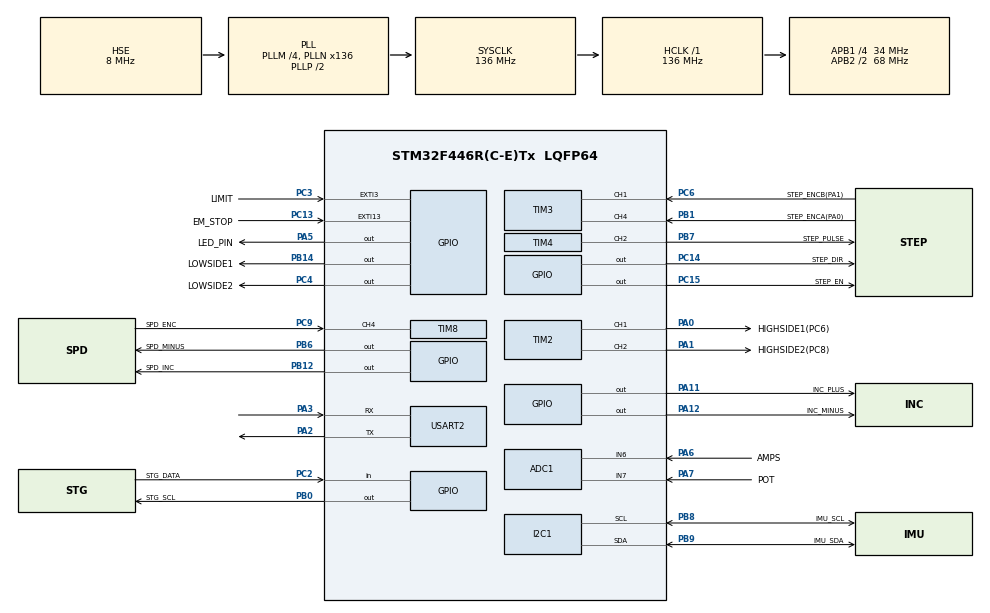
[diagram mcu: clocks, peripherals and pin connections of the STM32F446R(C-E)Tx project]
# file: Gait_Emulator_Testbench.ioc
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ADC1.Channel-2\#ChannelRegularConversion=ADC_CHANNEL_6
ADC1.NbrOfConversionFlag=1
ADC1.Rank-2\#ChannelRegularConversion=1
ADC1.SamplingTime-2\#ChannelRegularConversion=ADC_SAMPLETIME_3CYCLES
ADC1.master=1
Dma.ADC1.3.Direction=DMA_PERIPH_TO_MEMORY
Dma.ADC1.3.FIFOMode=DMA_FIFOMODE_DISABLE
Dma.ADC1.3.Instance=DMA2_Stream0
Dma.ADC1.3.MemDataAlignment=DMA_MDATAALIGN_HALFWORD
Dma.ADC1.3.MemInc=DMA_MINC_ENABLE
Dma.ADC1.3.Mode=DMA_CIRCULAR
Dma.ADC1.3.PeriphDataAlignment=DMA_PDATAALIGN_HALFWORD
Dma.ADC1.3.PeriphInc=DMA_PINC_DISABLE
Dma.ADC1.3.Priority=DMA_PRIORITY_LOW
Dma.I2C1_RX.4.Direction=DMA_PERIPH_TO_MEMORY
Dma.I2C1_RX.4.FIFOMode=DMA_FIFOMODE_DISABLE
Dma.I2C1_RX.4.Instance=DMA1_Stream0
Dma.I2C1_RX.4.MemDataAlignment=DMA_MDATAALIGN_BYTE
Dma.I2C1_RX.4.MemInc=DMA_MINC_ENABLE
Dma.I2C1_RX.4.Mode=DMA_CIRCULAR
Dma.I2C1_RX.4.PeriphDataAlignment=DMA_PDATAALIGN_BYTE
Dma.I2C1_RX.4.PeriphInc=DMA_PINC_DISABLE
Dma.I2C1_RX.4.Priority=DMA_PRIORITY_LOW
Dma.I2C1_TX.5.Direction=DMA_MEMORY_TO_PERIPH
Dma.I2C1_TX.5.FIFOMode=DMA_FIFOMODE_DISABLE
Dma.I2C1_TX.5.Instance=DMA1_Stream7
Dma.I2C1_TX.5.MemDataAlignment=DMA_MDATAALIGN_BYTE
Dma.I2C1_TX.5.MemInc=DMA_MINC_ENABLE
Dma.I2C1_TX.5.Mode=DMA_CIRCULAR
Dma.I2C1_TX.5.PeriphDataAlignment=DMA_PDATAALIGN_BYTE
Dma.I2C1_TX.5.PeriphInc=DMA_PINC_DISABLE
Dma.I2C1_TX.5.Priority=DMA_PRIORITY_LOW
Dma.Request0=TIM8_CH4/TRIG/COM
Dma.Request1=USART2_RX
Dma.Request2=USART2_TX
Dma.Request3=ADC1
Dma.Request4=I2C1_RX
Dma.Request5=I2C1_TX
Dma.Request6=TIM3_CH1/TRIG
Dma.Request7=TIM3_CH4/UP
Dma.TIM3_CH1/TRIG.6.Direction=DMA_PERIPH_TO_MEMORY
Dma.TIM3_CH1/TRIG.6.FIFOMode=DMA_FIFOMODE_DISABLE
Dma.TIM3_CH1/TRIG.6.Instance=DMA1_Stream4
Dma.TIM3_CH1/TRIG.6.MemDataAlignment=DMA_MDATAALIGN_HALFWORD
Dma.TIM3_CH1/TRIG.6.MemInc=DMA_MINC_ENABLE
Dma.TIM3_CH1/TRIG.6.Mode=DMA_CIRCULAR
Dma.TIM3_CH1/TRIG.6.PeriphDataAlignment=DMA_PDATAALIGN_HALFWORD
Dma.TIM3_CH1/TRIG.6.PeriphInc=DMA_PINC_DISABLE
Dma.TIM3_CH1/TRIG.6.Priority=DMA_PRIORITY_LOW
Dma.TIM3_CH4/UP.7.Direction=DMA_PERIPH_TO_MEMORY
Dma.TIM3_CH4/UP.7.FIFOMode=DMA_FIFOMODE_DISABLE
Dma.TIM3_CH4/UP.7.Instance=DMA1_Stream2
Dma.TIM3_CH4/UP.7.MemDataAlignment=DMA_MDATAALIGN_HALFWORD
Dma.TIM3_CH4/UP.7.MemInc=DMA_MINC_ENABLE
Dma.TIM3_CH4/UP.7.Mode=DMA_CIRCULAR
Dma.TIM3_CH4/UP.7.PeriphDataAlignment=DMA_PDATAALIGN_HALFWORD
Dma.TIM3_CH4/UP.7.PeriphInc=DMA_PINC_DISABLE
Dma.TIM3_CH4/UP.7.Priority=DMA_PRIORITY_LOW
Dma.TIM8_CH4/TRIG/COM.0.Direction=DMA_PERIPH_TO_MEMORY
Dma.TIM8_CH4/TRIG/COM.0.FIFOMode=DMA_FIFOMODE_DISABLE
Dma.TIM8_CH4/TRIG/COM.0.Instance=DMA2_Stream7
Dma.TIM8_CH4/TRIG/COM.0.MemDataAlignment=DMA_MDATAALIGN_HALFWORD
Dma.TIM8_CH4/TRIG/COM.0.MemInc=DMA_MINC_ENABLE
Dma.TIM8_CH4/TRIG/COM.0.Mode=DMA_NORMAL
Dma.TIM8_CH4/TRIG/COM.0.PeriphDataAlignment=DMA_PDATAALIGN_HALFWORD
Dma.TIM8_CH4/TRIG/COM.0.PeriphInc=DMA_PINC_DISABLE
Dma.TIM8_CH4/TRIG/COM.0.Priority=DMA_PRIORITY_LOW
Dma.USART2_RX.1.Direction=DMA_PERIPH_TO_MEMORY
Dma.USART2_RX.1.FIFOMode=DMA_FIFOMODE_DISABLE
Dma.USART2_RX.1.Instance=DMA1_Stream5
Dma.USART2_RX.1.MemDataAlignment=DMA_MDATAALIGN_BYTE
Dma.USART2_RX.1.MemInc=DMA_MINC_ENABLE
Dma.USART2_RX.1.Mode=DMA_NORMAL
Dma.USART2_RX.1.PeriphDataAlignment=DMA_PDATAALIGN_BYTE
Dma.USART2_RX.1.PeriphInc=DMA_PINC_DISABLE
Dma.USART2_RX.1.Priority=DMA_PRIORITY_LOW
Dma.USART2_TX.2.Direction=DMA_MEMORY_TO_PERIPH
Dma.USART2_TX.2.FIFOMode=DMA_FIFOMODE_DISABLE
Dma.USART2_TX.2.Instance=DMA1_Stream6
Dma.USART2_TX.2.MemDataAlignment=DMA_MDATAALIGN_BYTE
Dma.USART2_TX.2.MemInc=DMA_MINC_ENABLE
Dma.USART2_TX.2.Mode=DMA_NORMAL
Dma.USART2_TX.2.PeriphDataAlignment=DMA_PDATAALIGN_BYTE
Dma.USART2_TX.2.PeriphInc=DMA_PINC_DISABLE
Dma.USART2_TX.2.Priority=DMA_PRIORITY_LOW
FREERTOS.INCLUDE_uxTaskGetStackHighWaterMark=1
FREERTOS.INCLUDE_vTaskDelete=0
FREERTOS.INCLUDE_xQueueGetMutexHolder=0
FREERTOS.INCLUDE_xTaskGetCurrentTaskHandle=0
FREERTOS.Tasks01=defaultTask,-2,128,StartDefaultTask,As weak,NULL,Static,defaultTaskBuffer,defaultTaskControlBlock;SpinVcp,1,512,CommTask,As external,NULL,Static,SpinVcpBuffer,SpinVcpControlBlock;StateMachine,0,2048,StateMachineTask,As external,NULL,Static,StateMachineBuffer,StateMachineControlBlock;SampleSensors,2,1024,SensorSamplingTask,As external,NULL,Static,SampleSensorsBuffer,SampleSensorsControlBlock
FREERTOS.Timers01=CommWatchdog,CommDisconnected,osTimerOnce,As external,NULL,Static,CommWatchdogControlBlock
FREERTOS.configENABLE_FPU=1
FREERTOS.configGENERATE_RUN_TIME_STATS=1
FREERTOS.configUSE_MUTEXES=0
FREERTOS.configUSE_NEWLIB_REENTRANT=1
FREERTOS.configUSE_STATS_FORMATTING_FUNCTIONS=1
FREERTOS.configUSE_TIMERS=1
FREERTOS.configUSE_TRACE_FACILITY=1
Mcu.Family=STM32F4
Mcu.Name=STM32F446R(C-E)Tx
Mcu.Package=LQFP64
Mcu.UserConstants=DATA_READY,(1UL << 3);COMM_TX,(1UL << 1);STATE_CHANGE,(1UL << 2);ENABLE_SAMPLING,(1UL << 4);COMM_RX,(1UL << 0);SENSORS_SAMPLED,(1UL << 5)
NVIC.DMA1_Stream0_IRQn=true\:5\:0\:false\:false\:true\:true\:false\:true\:true
NVIC.DMA1_Stream2_IRQn=true\:5\:0\:false\:false\:true\:true\:false\:true\:true
NVIC.DMA1_Stream4_IRQn=true\:5\:0\:false\:false\:true\:true\:false\:true\:true
NVIC.DMA1_Stream5_IRQn=true\:5\:0\:false\:false\:true\:true\:false\:true\:true
NVIC.DMA1_Stream6_IRQn=true\:5\:0\:false\:false\:true\:true\:false\:true\:true
NVIC.DMA1_Stream7_IRQn=true\:5\:0\:false\:false\:true\:true\:false\:true\:true
NVIC.DMA2_Stream0_IRQn=true\:5\:0\:false\:false\:true\:true\:false\:true\:true
NVIC.DMA2_Stream7_IRQn=true\:5\:0\:false\:false\:true\:true\:false\:true\:true
NVIC.EXTI15_10_IRQn=true\:5\:0\:false\:false\:true\:true\:true\:true\:true
NVIC.EXTI3_IRQn=true\:5\:0\:false\:false\:true\:true\:true\:true\:true
NVIC.PriorityGroup=NVIC_PRIORITYGROUP_4
NVIC.TIM4_IRQn=true\:5\:0\:false\:false\:true\:true\:true\:true\:true
NVIC.TIM6_DAC_IRQn=true\:15\:0\:false\:false\:true\:false\:false\:true\:true
NVIC.TimeBase=TIM6_DAC_IRQn
NVIC.TimeBaseIP=TIM6
PA0-WKUP.GPIO_Label=HIGHSIDE1(PC6)
PA0-WKUP.Signal=S_TIM2_CH1_ETR
PA1.GPIO_Label=HIGHSIDE2(PC8)
PA1.Signal=S_TIM2_CH2
PA11.GPIO_Label=INC_PLUS
PA11.Signal=GPIO_Output
PA12.GPIO_Label=INC_MINUS
PA12.Signal=GPIO_Output
PA13.GPIO_Label=TMS
PA13.Mode=Serial_Wire
PA13.Signal=SYS_JTMS-SWDIO
PA14.GPIO_Label=TCK
PA14.Mode=Serial_Wire
PA14.Signal=SYS_JTCK-SWCLK
PA2.Mode=Asynchronous
PA2.Signal=USART2_TX
PA3.Mode=Asynchronous
PA3.Signal=USART2_RX
PA5.GPIO_Label=LED_PIN
PA5.Signal=GPIO_Output
PA6.GPIO_Label=AMPS
PA6.Signal=ADCx_IN6
PA7.GPIO_Label=POT
PA7.Signal=ADCx_IN7
PB0.GPIO_Label=STG_SCL
PB0.Signal=GPIO_Output
PB1.GPIO_Label=STEP_ENCA(PA0)
PB1.Signal=S_TIM3_CH4
PB12.GPIO_Label=SPD_INC
PB12.Signal=GPIO_Output
PB14.GPIO_Label=LOWSIDE1
PB14.Signal=GPIO_Output
PB6.GPIO_Label=SPD_MINUS
PB6.Signal=GPIO_Output
PB7.GPIO_Label=STEP_PULSE
PB7.Signal=S_TIM4_CH2
PB8.GPIO_Label=IMU_SCL
PB8.Mode=I2C
PB8.Signal=I2C1_SCL
PB9.GPIO_Label=IMU_SDA
PB9.Mode=I2C
PB9.Signal=I2C1_SDA
PC13.GPIO_Label=EM_STOP
PC13.GPIO_ModeDefaultEXTI=GPIO_MODE_IT_FALLING
PC13.Signal=GPXTI13
PC14-OSC32_IN.GPIO_Label=STEP_DIR
PC14-OSC32_IN.Signal=GPIO_Output
PC15-OSC32_OUT.GPIO_Label=STEP_EN
PC15-OSC32_OUT.Signal=GPIO_Output
PC2.GPIO_Label=STG_DATA
PC2.Signal=GPIO_Input
PC3.GPIO_Label=LIMIT
PC3.GPIO_ModeDefaultEXTI=GPIO_MODE_IT_FALLING
PC3.Signal=GPXTI3
PC4.GPIO_Label=LOWSIDE2
PC4.Signal=GPIO_Output
PC6.GPIO_Label=STEP_ENCB(PA1)
PC6.Signal=S_TIM3_CH1
PC9.GPIO_Label=SPD_ENC
PC9.Signal=S_TIM8_CH4
PH0-OSC_IN.Mode=HSE-External-Oscillator
PH0-OSC_IN.Signal=RCC_OSC_IN
PH1-OSC_OUT.Mode=HSE-External-Oscillator
PH1-OSC_OUT.Signal=RCC_OSC_OUT
ProjectManager.HeapSize=0x200
ProjectManager.StackSize=0x400
ProjectManager.TargetToolchain=STM32CubeIDE
RCC.48MHZClocksFreq_Value=84000000
RCC.AHBFreq_Value=136000000
RCC.APB1CLKDivider=RCC_HCLK_DIV4
RCC.APB1Freq_Value=34000000
RCC.APB1TimFreq_Value=68000000
RCC.APB2CLKDivider=RCC_HCLK_DIV2
RCC.APB2Freq_Value=68000000
RCC.APB2TimFreq_Value=136000000
RCC.CortexFreq_Value=136000000
RCC.FLatency-AdvancedSettings=FLASH_LATENCY_4
RCC.HCLKFreq_Value=136000000
RCC.HSE_VALUE=8000000
RCC.HSI_VALUE=16000000
RCC.PLLM=4
RCC.PLLN=136
RCC.PLLSourceVirtual=RCC_PLLSOURCE_HSE
RCC.SYSCLKFreq_VALUE=136000000
RCC.SYSCLKSource=RCC_SYSCLKSOURCE_PLLCLK
RCC.USBFreq_Value=136000000
RCC.VCOOutputFreq_Value=272000000
SH.ADCx_IN6.0=ADC1_IN6,IN6
SH.ADCx_IN7.0=ADC1_IN7,IN7
SH.S_TIM2_CH1_ETR.0=TIM2_CH1,PWM Generation1 CH1
SH.S_TIM2_CH2.0=TIM2_CH2,PWM Generation2 CH2
SH.S_TIM3_CH1.0=TIM3_CH1,Input_Capture1_from_TI1
SH.S_TIM3_CH4.0=TIM3_CH4,Input_Capture4_from_TI4
SH.S_TIM4_CH2.0=TIM4_CH2,PWM Generation2 CH2
SH.S_TIM8_CH4.0=TIM8_CH4,Input_Capture4_from_TI4
TIM2.Channel-PWM\ Generation1\ CH1=TIM_CHANNEL_1
TIM2.Channel-PWM\ Generation2\ CH2=TIM_CHANNEL_2
TIM3.Channel-Input_Capture1_from_TI1=TIM_CHANNEL_1
TIM3.Channel-Input_Capture4_from_TI4=TIM_CHANNEL_4
TIM4.Channel-PWM\ Generation2\ CH2=TIM_CHANNEL_2
TIM8.Channel-Input_Capture4_from_TI4=TIM_CHANNEL_4
TIM8.Period=200
TIM8.Prescaler=84-1
USART2.VirtualMode=VM_ASYNC
VP_FREERTOS_VS_CMSIS_V1.Mode=CMSIS_V1
VP_SYS_VS_tim6.Mode=TIM6
VP_TIM4_VS_ClockSourceINT.Mode=Internal
VP_TIM7_VS_ClockSourceINT.Mode=Enable_Timer
VP_TIM8_VS_ClockSourceINT.Mode=Internal
board=NUCLEO-F446RE

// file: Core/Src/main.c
/* USER CODE BEGIN Header */
/**
  ******************************************************************************
  * @file           : main.c
  * @brief          : Main program body
  ******************************************************************************
  * @attention
  *
  * Copyright (c) 2025 STMicroelectronics.
  * All rights reserved.
  *
  * This software is licensed under terms that can be found in the LICENSE file
  * in the root directory of this software component.
  * If no LICENSE file comes with this software, it is provided AS-IS.
  *
  ******************************************************************************
  */
/* USER CODE END Header */
#include "main.h"
#include "cmsis_os.h"

/* USER CODE BEGIN Includes */

#include "CommTask.h"
#include "StateMachineTask.h"
#include "SensorSamplingTask.h"

/* USER CODE END Includes */

ADC_HandleTypeDef hadc1;
DMA_HandleTypeDef hdma_adc1;

I2C_HandleTypeDef hi2c1;
DMA_HandleTypeDef hdma_i2c1_rx;
DMA_HandleTypeDef hdma_i2c1_tx;

TIM_HandleTypeDef htim2;
TIM_HandleTypeDef htim3;
TIM_HandleTypeDef htim4;
TIM_HandleTypeDef htim7;
TIM_HandleTypeDef htim8;
DMA_HandleTypeDef hdma_tim3_ch1_trig;
DMA_HandleTypeDef hdma_tim3_ch4_up;
DMA_HandleTypeDef hdma_tim8_ch4_trig_com;

UART_HandleTypeDef huart2;
DMA_HandleTypeDef hdma_usart2_rx;
DMA_HandleTypeDef hdma_usart2_tx;

osThreadId defaultTaskHandle;
uint32_t defaultTaskBuffer[ 128 ];
osStaticThreadDef_t defaultTaskControlBlock;
osThreadId SpinVcpHandle;
uint32_t SpinVcpBuffer[ 512 ];
osStaticThreadDef_t SpinVcpControlBlock;
osThreadId StateMachineHandle;
uint32_t StateMachineBuffer[ 2048 ];
osStaticThreadDef_t StateMachineControlBlock;
osThreadId SampleSensorsHandle;
uint32_t SampleSensorsBuffer[ 1024 ];
osStaticThreadDef_t SampleSensorsControlBlock;
osTimerId CommWatchdogHandle;
osStaticTimerDef_t CommWatchdogControlBlock;

void SystemClock_Config(void);
static void MX_GPIO_Init(void);
static void MX_DMA_Init(void);
static void MX_ADC1_Init(void);
static void MX_TIM8_Init(void);
static void MX_TIM3_Init(void);
static void MX_USART2_UART_Init(void);
static void MX_TIM2_Init(void);
static void MX_TIM4_Init(void);
static void MX_I2C1_Init(void);
static void MX_TIM7_Init(void);
void StartDefaultTask(void const * argument);
extern void CommTask(void const * argument);
extern void StateMachineTask(void const * argument);
extern void SensorSamplingTask(void const * argument);
extern void CommDisconnected(void const * argument);

int main(void)
{

  /* MCU Configuration--------------------------------------------------------*/

  /* Reset of all peripherals, Initializes the Flash interface and the Systick. */
  HAL_Init();

  /* Configure the system clock */
  SystemClock_Config();

  /* Initialize all configured peripherals */
  MX_GPIO_Init();
  MX_DMA_Init();
  MX_ADC1_Init();
  MX_TIM8_Init();
  MX_TIM3_Init();
  MX_USART2_UART_Init();
  MX_TIM2_Init();
  MX_TIM4_Init();
  MX_I2C1_Init();
  MX_TIM7_Init();

  /* Create the timer(s) */
  /* definition and creation of CommWatchdog */
  osTimerStaticDef(CommWatchdog, CommDisconnected, &CommWatchdogControlBlock);
  CommWatchdogHandle = osTimerCreate(osTimer(CommWatchdog), osTimerOnce, NULL);

  /* Create the thread(s) */
  /* definition and creation of defaultTask */
  osThreadStaticDef(defaultTask, StartDefaultTask, osPriorityLow, 0, 128, defaultTaskBuffer, &defaultTaskControlBlock);
  defaultTaskHandle = osThreadCreate(osThread(defaultTask), NULL);

  /* definition and creation of SpinVcp */
  osThreadStaticDef(SpinVcp, CommTask, osPriorityAboveNormal, 0, 512, SpinVcpBuffer, &SpinVcpControlBlock);
  SpinVcpHandle = osThreadCreate(osThread(SpinVcp), NULL);

  /* definition and creation of StateMachine */
  osThreadStaticDef(StateMachine, StateMachineTask, osPriorityNormal, 0, 2048, StateMachineBuffer, &StateMachineControlBlock);
  StateMachineHandle = osThreadCreate(osThread(StateMachine), NULL);

  /* definition and creation of SampleSensors */
  osThreadStaticDef(SampleSensors, SensorSamplingTask, osPriorityHigh, 0, 1024, SampleSensorsBuffer, &SampleSensorsControlBlock);
  SampleSensorsHandle = osThreadCreate(osThread(SampleSensors), NULL);

  /* Start scheduler */
  osKernelStart();

  /* We should never get here as control is now taken by the scheduler */

  /* Infinite loop */
  while (1)
  {

  }
}

void SystemClock_Config(void)
{
  RCC_OscInitTypeDef RCC_OscInitStruct = {0};
  RCC_ClkInitTypeDef RCC_ClkInitStruct = {0};

  /** Configure the main internal regulator output voltage
  */
  __HAL_RCC_PWR_CLK_ENABLE();
  __HAL_PWR_VOLTAGESCALING_CONFIG(PWR_REGULATOR_VOLTAGE_SCALE2);

  /** Initializes the RCC Oscillators according to the specified parameters
  * in the RCC_OscInitTypeDef structure.
  */
  RCC_OscInitStruct.OscillatorType = RCC_OSCILLATORTYPE_HSE;
  RCC_OscInitStruct.HSEState = RCC_HSE_ON;
  RCC_OscInitStruct.PLL.PLLState = RCC_PLL_ON;
  RCC_OscInitStruct.PLL.PLLSource = RCC_PLLSOURCE_HSE;
  RCC_OscInitStruct.PLL.PLLM = 4;
  RCC_OscInitStruct.PLL.PLLN = 136;
  RCC_OscInitStruct.PLL.PLLP = RCC_PLLP_DIV2;
  RCC_OscInitStruct.PLL.PLLQ = 2;
  RCC_OscInitStruct.PLL.PLLR = 2;
  if (HAL_RCC_OscConfig(&RCC_OscInitStruct) != HAL_OK)
  {
    Error_Handler();
  }

  /** Initializes the CPU, AHB and APB buses clocks
  */
  RCC_ClkInitStruct.ClockType = RCC_CLOCKTYPE_HCLK|RCC_CLOCKTYPE_SYSCLK
                              |RCC_CLOCKTYPE_PCLK1|RCC_CLOCKTYPE_PCLK2;
  RCC_ClkInitStruct.SYSCLKSource = RCC_SYSCLKSOURCE_PLLCLK;
  RCC_ClkInitStruct.AHBCLKDivider = RCC_SYSCLK_DIV1;
  RCC_ClkInitStruct.APB1CLKDivider = RCC_HCLK_DIV4;
  RCC_ClkInitStruct.APB2CLKDivider = RCC_HCLK_DIV2;

  if (HAL_RCC_ClockConfig(&RCC_ClkInitStruct, FLASH_LATENCY_4) != HAL_OK)
  {
    Error_Handler();
  }
}

static void MX_ADC1_Init(void)
{

  ADC_ChannelConfTypeDef sConfig = {0};

  /** Configure the global features of the ADC (Clock, Resolution, Data Alignment and number of conversion)
  */
  hadc1.Instance = ADC1;
  hadc1.Init.ClockPrescaler = ADC_CLOCK_SYNC_PCLK_DIV2;
  hadc1.Init.Resolution = ADC_RESOLUTION_12B;
  hadc1.Init.ScanConvMode = DISABLE;
  hadc1.Init.ContinuousConvMode = DISABLE;
  hadc1.Init.DiscontinuousConvMode = DISABLE;
  hadc1.Init.ExternalTrigConvEdge = ADC_EXTERNALTRIGCONVEDGE_NONE;
  hadc1.Init.ExternalTrigConv = ADC_SOFTWARE_START;
  hadc1.Init.DataAlign = ADC_DATAALIGN_RIGHT;
  hadc1.Init.NbrOfConversion = 1;
  hadc1.Init.DMAContinuousRequests = DISABLE;
  hadc1.Init.EOCSelection = ADC_EOC_SINGLE_CONV;
  if (HAL_ADC_Init(&hadc1) != HAL_OK)
  {
    Error_Handler();
  }

  /** Configure for the selected ADC regular channel its corresponding rank in the sequencer and its sample time.
  */
  sConfig.Channel = ADC_CHANNEL_6;
  sConfig.Rank = 1;
  sConfig.SamplingTime = ADC_SAMPLETIME_3CYCLES;
  if (HAL_ADC_ConfigChannel(&hadc1, &sConfig) != HAL_OK)
  {
    Error_Handler();
  }

}

static void MX_I2C1_Init(void)
{

  hi2c1.Instance = I2C1;
  hi2c1.Init.ClockSpeed = 100000;
  hi2c1.Init.DutyCycle = I2C_DUTYCYCLE_2;
  hi2c1.Init.OwnAddress1 = 0;
  hi2c1.Init.AddressingMode = I2C_ADDRESSINGMODE_7BIT;
  hi2c1.Init.DualAddressMode = I2C_DUALADDRESS_DISABLE;
  hi2c1.Init.OwnAddress2 = 0;
  hi2c1.Init.GeneralCallMode = I2C_GENERALCALL_DISABLE;
  hi2c1.Init.NoStretchMode = I2C_NOSTRETCH_DISABLE;
  if (HAL_I2C_Init(&hi2c1) != HAL_OK)
  {
    Error_Handler();
  }

}

static void MX_TIM2_Init(void)
{

  TIM_MasterConfigTypeDef sMasterConfig = {0};
  TIM_OC_InitTypeDef sConfigOC = {0};

  htim2.Instance = TIM2;
  htim2.Init.Prescaler = 0;
  htim2.Init.CounterMode = TIM_COUNTERMODE_UP;
  htim2.Init.Period = 4294967295;
  htim2.Init.ClockDivision = TIM_CLOCKDIVISION_DIV1;
  htim2.Init.AutoReloadPreload = TIM_AUTORELOAD_PRELOAD_DISABLE;
  if (HAL_TIM_PWM_Init(&htim2) != HAL_OK)
  {
    Error_Handler();
  }
  sMasterConfig.MasterOutputTrigger = TIM_TRGO_RESET;
  sMasterConfig.MasterSlaveMode = TIM_MASTERSLAVEMODE_DISABLE;
  if (HAL_TIMEx_MasterConfigSynchronization(&htim2, &sMasterConfig) != HAL_OK)
  {
    Error_Handler();
  }
  sConfigOC.OCMode = TIM_OCMODE_PWM1;
  sConfigOC.Pulse = 0;
  sConfigOC.OCPolarity = TIM_OCPOLARITY_HIGH;
  sConfigOC.OCFastMode = TIM_OCFAST_DISABLE;
  if (HAL_TIM_PWM_ConfigChannel(&htim2, &sConfigOC, TIM_CHANNEL_1) != HAL_OK)
  {
    Error_Handler();
  }
  if (HAL_TIM_PWM_ConfigChannel(&htim2, &sConfigOC, TIM_CHANNEL_2) != HAL_OK)
  {
    Error_Handler();
  }
  HAL_TIM_MspPostInit(&htim2);

}

static void MX_TIM3_Init(void)
{

  TIM_MasterConfigTypeDef sMasterConfig = {0};
  TIM_IC_InitTypeDef sConfigIC = {0};

  htim3.Instance = TIM3;
  htim3.Init.Prescaler = 0;
  htim3.Init.CounterMode = TIM_COUNTERMODE_UP;
  htim3.Init.Period = 65535;
  htim3.Init.ClockDivision = TIM_CLOCKDIVISION_DIV1;
  htim3.Init.AutoReloadPreload = TIM_AUTORELOAD_PRELOAD_DISABLE;
  if (HAL_TIM_IC_Init(&htim3) != HAL_OK)
  {
    Error_Handler();
  }
  sMasterConfig.MasterOutputTrigger = TIM_TRGO_RESET;
  sMasterConfig.MasterSlaveMode = TIM_MASTERSLAVEMODE_DISABLE;
  if (HAL_TIMEx_MasterConfigSynchronization(&htim3, &sMasterConfig) != HAL_OK)
  {
    Error_Handler();
  }
  sConfigIC.ICPolarity = TIM_INPUTCHANNELPOLARITY_RISING;
  sConfigIC.ICSelection = TIM_ICSELECTION_DIRECTTI;
  sConfigIC.ICPrescaler = TIM_ICPSC_DIV1;
  sConfigIC.ICFilter = 0;
  if (HAL_TIM_IC_ConfigChannel(&htim3, &sConfigIC, TIM_CHANNEL_1) != HAL_OK)
  {
    Error_Handler();
  }
  if (HAL_TIM_IC_ConfigChannel(&htim3, &sConfigIC, TIM_CHANNEL_4) != HAL_OK)
  {
    Error_Handler();
  }

}

static void MX_TIM4_Init(void)
{

  TIM_ClockConfigTypeDef sClockSourceConfig = {0};
  TIM_MasterConfigTypeDef sMasterConfig = {0};
  TIM_OC_InitTypeDef sConfigOC = {0};

  htim4.Instance = TIM4;
  htim4.Init.Prescaler = 0;
  htim4.Init.CounterMode = TIM_COUNTERMODE_UP;
  htim4.Init.Period = 65535;
  htim4.Init.ClockDivision = TIM_CLOCKDIVISION_DIV1;
  htim4.Init.AutoReloadPreload = TIM_AUTORELOAD_PRELOAD_DISABLE;
  if (HAL_TIM_Base_Init(&htim4) != HAL_OK)
  {
    Error_Handler();
  }
  sClockSourceConfig.ClockSource = TIM_CLOCKSOURCE_INTERNAL;
  if (HAL_TIM_ConfigClockSource(&htim4, &sClockSourceConfig) != HAL_OK)
  {
    Error_Handler();
  }
  if (HAL_TIM_PWM_Init(&htim4) != HAL_OK)
  {
    Error_Handler();
  }
  sMasterConfig.MasterOutputTrigger = TIM_TRGO_RESET;
  sMasterConfig.MasterSlaveMode = TIM_MASTERSLAVEMODE_DISABLE;
  if (HAL_TIMEx_MasterConfigSynchronization(&htim4, &sMasterConfig) != HAL_OK)
  {
    Error_Handler();
  }
  sConfigOC.OCMode = TIM_OCMODE_PWM1;
  sConfigOC.Pulse = 0;
  sConfigOC.OCPolarity = TIM_OCPOLARITY_HIGH;
  sConfigOC.OCFastMode = TIM_OCFAST_DISABLE;
  if (HAL_TIM_PWM_ConfigChannel(&htim4, &sConfigOC, TIM_CHANNEL_2) != HAL_OK)
  {
    Error_Handler();
  }
  HAL_TIM_MspPostInit(&htim4);

}

static void MX_TIM7_Init(void)
{

  TIM_MasterConfigTypeDef sMasterConfig = {0};

  htim7.Instance = TIM7;
  htim7.Init.Prescaler = 0;
  htim7.Init.CounterMode = TIM_COUNTERMODE_UP;
  htim7.Init.Period = 65535;
  htim7.Init.AutoReloadPreload = TIM_AUTORELOAD_PRELOAD_DISABLE;
  if (HAL_TIM_Base_Init(&htim7) != HAL_OK)
  {
    Error_Handler();
  }
  sMasterConfig.MasterOutputTrigger = TIM_TRGO_RESET;
  sMasterConfig.MasterSlaveMode = TIM_MASTERSLAVEMODE_DISABLE;
  if (HAL_TIMEx_MasterConfigSynchronization(&htim7, &sMasterConfig) != HAL_OK)
  {
    Error_Handler();
  }

}

static void MX_TIM8_Init(void)
{

  TIM_ClockConfigTypeDef sClockSourceConfig = {0};
  TIM_MasterConfigTypeDef sMasterConfig = {0};
  TIM_IC_InitTypeDef sConfigIC = {0};

  htim8.Instance = TIM8;
  htim8.Init.Prescaler = 84-1;
  htim8.Init.CounterMode = TIM_COUNTERMODE_UP;
  htim8.Init.Period = 200;
  htim8.Init.ClockDivision = TIM_CLOCKDIVISION_DIV1;
  htim8.Init.RepetitionCounter = 0;
  htim8.Init.AutoReloadPreload = TIM_AUTORELOAD_PRELOAD_DISABLE;
  if (HAL_TIM_Base_Init(&htim8) != HAL_OK)
  {
    Error_Handler();
  }
  sClockSourceConfig.ClockSource = TIM_CLOCKSOURCE_INTERNAL;
  if (HAL_TIM_ConfigClockSource(&htim8, &sClockSourceConfig) != HAL_OK)
  {
    Error_Handler();
  }
  if (HAL_TIM_IC_Init(&htim8) != HAL_OK)
  {
    Error_Handler();
  }
  sMasterConfig.MasterOutputTrigger = TIM_TRGO_RESET;
  sMasterConfig.MasterSlaveMode = TIM_MASTERSLAVEMODE_DISABLE;
  if (HAL_TIMEx_MasterConfigSynchronization(&htim8, &sMasterConfig) != HAL_OK)
  {
    Error_Handler();
  }
  sConfigIC.ICPolarity = TIM_INPUTCHANNELPOLARITY_RISING;
  sConfigIC.ICSelection = TIM_ICSELECTION_DIRECTTI;
  sConfigIC.ICPrescaler = TIM_ICPSC_DIV1;
  sConfigIC.ICFilter = 0;
  if (HAL_TIM_IC_ConfigChannel(&htim8, &sConfigIC, TIM_CHANNEL_4) != HAL_OK)
  {
    Error_Handler();
  }

}

static void MX_USART2_UART_Init(void)
{

  huart2.Instance = USART2;
  huart2.Init.BaudRate = 115200;
  huart2.Init.WordLength = UART_WORDLENGTH_8B;
  huart2.Init.StopBits = UART_STOPBITS_1;
  huart2.Init.Parity = UART_PARITY_NONE;
  huart2.Init.Mode = UART_MODE_TX_RX;
  huart2.Init.HwFlowCtl = UART_HWCONTROL_NONE;
  huart2.Init.OverSampling = UART_OVERSAMPLING_16;
  if (HAL_UART_Init(&huart2) != HAL_OK)
  {
    Error_Handler();
  }

}

static void MX_DMA_Init(void)
{

  /* DMA controller clock enable */
  __HAL_RCC_DMA2_CLK_ENABLE();
  __HAL_RCC_DMA1_CLK_ENABLE();

  /* DMA interrupt init */
  /* DMA1_Stream0_IRQn interrupt configuration */
  HAL_NVIC_SetPriority(DMA1_Stream0_IRQn, 5, 0);
  HAL_NVIC_EnableIRQ(DMA1_Stream0_IRQn);
  /* DMA1_Stream2_IRQn interrupt configuration */
  HAL_NVIC_SetPriority(DMA1_Stream2_IRQn, 5, 0);
  HAL_NVIC_EnableIRQ(DMA1_Stream2_IRQn);
  /* DMA1_Stream4_IRQn interrupt configuration */
  HAL_NVIC_SetPriority(DMA1_Stream4_IRQn, 5, 0);
  HAL_NVIC_EnableIRQ(DMA1_Stream4_IRQn);
  /* DMA1_Stream5_IRQn interrupt configuration */
  HAL_NVIC_SetPriority(DMA1_Stream5_IRQn, 5, 0);
  HAL_NVIC_EnableIRQ(DMA1_Stream5_IRQn);
  /* DMA1_Stream6_IRQn interrupt configuration */
  HAL_NVIC_SetPriority(DMA1_Stream6_IRQn, 5, 0);
  HAL_NVIC_EnableIRQ(DMA1_Stream6_IRQn);
  /* DMA1_Stream7_IRQn interrupt configuration */
  HAL_NVIC_SetPriority(DMA1_Stream7_IRQn, 5, 0);
  HAL_NVIC_EnableIRQ(DMA1_Stream7_IRQn);
  /* DMA2_Stream0_IRQn interrupt configuration */
  HAL_NVIC_SetPriority(DMA2_Stream0_IRQn, 5, 0);
  HAL_NVIC_EnableIRQ(DMA2_Stream0_IRQn);
  /* DMA2_Stream7_IRQn interrupt configuration */
  HAL_NVIC_SetPriority(DMA2_Stream7_IRQn, 5, 0);
  HAL_NVIC_EnableIRQ(DMA2_Stream7_IRQn);

}

static void MX_GPIO_Init(void)
{
  GPIO_InitTypeDef GPIO_InitStruct = {0};

  /* GPIO Ports Clock Enable */
  __HAL_RCC_GPIOC_CLK_ENABLE();
  __HAL_RCC_GPIOH_CLK_ENABLE();
  __HAL_RCC_GPIOA_CLK_ENABLE();
  __HAL_RCC_GPIOB_CLK_ENABLE();

  /*Configure GPIO pin Output Level */
  HAL_GPIO_WritePin(GPIOC, STEP_DIR_Pin|STEP_EN_Pin|LOWSIDE2_Pin, GPIO_PIN_RESET);

  /*Configure GPIO pin Output Level */
  HAL_GPIO_WritePin(GPIOA, LED_PIN_Pin|INC_PLUS_Pin|INC_MINUS_Pin, GPIO_PIN_RESET);

  /*Configure GPIO pin Output Level */
  HAL_GPIO_WritePin(GPIOB, STG_SCL_Pin|SPD_INC_Pin|LOWSIDE1_Pin|SPD_MINUS_Pin, GPIO_PIN_RESET);

  /*Configure GPIO pins : EM_STOP_Pin LIMIT_Pin */
  GPIO_InitStruct.Pin = EM_STOP_Pin|LIMIT_Pin;
  GPIO_InitStruct.Mode = GPIO_MODE_IT_FALLING;
  GPIO_InitStruct.Pull = GPIO_NOPULL;
  HAL_GPIO_Init(GPIOC, &GPIO_InitStruct);

  /*Configure GPIO pins : STEP_DIR_Pin STEP_EN_Pin LOWSIDE2_Pin */
  GPIO_InitStruct.Pin = STEP_DIR_Pin|STEP_EN_Pin|LOWSIDE2_Pin;
  GPIO_InitStruct.Mode = GPIO_MODE_OUTPUT_PP;
  GPIO_InitStruct.Pull = GPIO_NOPULL;
  GPIO_InitStruct.Speed = GPIO_SPEED_FREQ_LOW;
  HAL_GPIO_Init(GPIOC, &GPIO_InitStruct);

  /*Configure GPIO pin : STG_DATA_Pin */
  GPIO_InitStruct.Pin = STG_DATA_Pin;
  GPIO_InitStruct.Mode = GPIO_MODE_INPUT;
  GPIO_InitStruct.Pull = GPIO_NOPULL;
  HAL_GPIO_Init(STG_DATA_GPIO_Port, &GPIO_InitStruct);

  /*Configure GPIO pins : LED_PIN_Pin INC_PLUS_Pin INC_MINUS_Pin */
  GPIO_InitStruct.Pin = LED_PIN_Pin|INC_PLUS_Pin|INC_MINUS_Pin;
  GPIO_InitStruct.Mode = GPIO_MODE_OUTPUT_PP;
  GPIO_InitStruct.Pull = GPIO_NOPULL;
  GPIO_InitStruct.Speed = GPIO_SPEED_FREQ_LOW;
  HAL_GPIO_Init(GPIOA, &GPIO_InitStruct);

  /*Configure GPIO pins : STG_SCL_Pin SPD_INC_Pin LOWSIDE1_Pin SPD_MINUS_Pin */
  GPIO_InitStruct.Pin = STG_SCL_Pin|SPD_INC_Pin|LOWSIDE1_Pin|SPD_MINUS_Pin;
  GPIO_InitStruct.Mode = GPIO_MODE_OUTPUT_PP;
  GPIO_InitStruct.Pull = GPIO_NOPULL;
  GPIO_InitStruct.Speed = GPIO_SPEED_FREQ_LOW;
  HAL_GPIO_Init(GPIOB, &GPIO_InitStruct);

  /* EXTI interrupt init*/
  HAL_NVIC_SetPriority(EXTI3_IRQn, 5, 0);
  HAL_NVIC_EnableIRQ(EXTI3_IRQn);

  HAL_NVIC_SetPriority(EXTI15_10_IRQn, 5, 0);
  HAL_NVIC_EnableIRQ(EXTI15_10_IRQn);

}

__weak void StartDefaultTask(void const * argument)
{
  for(;;)
  {
    osDelay(1);
  }
}

void HAL_TIM_PeriodElapsedCallback(TIM_HandleTypeDef *htim)
{
  if (htim->Instance == TIM6) {
    HAL_IncTick();
  }
}

void Error_Handler(void)
{
  __disable_irq();
  while (1)
  {
  }
}
